# ESP32-C6 register map
Vendor: ESPRESSIF SYSTEMS (SHANGHAI) CO., LTD.; Series: ESP32 C-Series; File version: 12
CPU: RV32IMAC r0p0, little endian, no MPU, no FPU, 0 interrupt priority bits
Address unit: 32 bits
Registers are 32-bit, read-write, reset 0x0 unless marked. A register's access mark holds for its fields unless they carry their own. Offsets are from the block's base; [hi:lo] are bit positions; lines under a group give offsets from that group; {n}, {i} and the like mark numbered series.

## SYSTIMER — System Timer
Base 0x6000A000
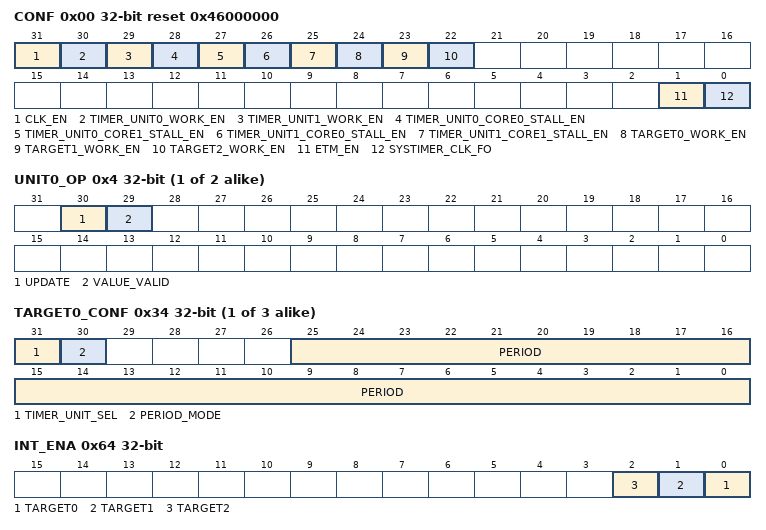
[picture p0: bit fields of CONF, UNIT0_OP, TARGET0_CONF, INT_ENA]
0x00 CONF reset 0x46000000 — Configure system timer clock
  [31] CLK_EN — register file clk gating
  [30] TIMER_UNIT0_WORK_EN — timer unit0 work enable
  [29] TIMER_UNIT1_WORK_EN — timer unit1 work enable
  [28] TIMER_UNIT0_CORE0_STALL_EN — If timer unit0 is stalled when core0 stalled
  [27] TIMER_UNIT0_CORE1_STALL_EN — If timer unit0 is stalled when core1 stalled
  [26] TIMER_UNIT1_CORE0_STALL_EN — If timer unit1 is stalled when core0 stalled
  [25] TIMER_UNIT1_CORE1_STALL_EN — If timer unit1 is stalled when core1 stalled
  [24] TARGET0_WORK_EN — target0 work enable
  [23] TARGET1_WORK_EN — target1 work enable
  [22] TARGET2_WORK_EN — target2 work enable
  [1] ETM_EN — enable systimer's etm task and event
  [0] SYSTIMER_CLK_FO — systimer clock force on
{0x4+4i} UNIT{i}_OP (i=0..1) access per field — system timer unit{i} value update register
  [30] UPDATE wo — update timer_unit0
  [29] VALUE_VALID ro — timer value is sync and valid
{0xC+8i} UNIT{i}LOAD (i=0..1) group — Cluster UNIT{i}LOAD, containing UNIT?_LOAD_HI, UNIT?_LOAD_LO
  0x00 HI — system timer unit0 value high load register
    [19:0] LOAD_HI — timer unit0 load high 20 bits
  0x04 LO — system timer unit0 value low load register
    [31:0] LOAD_LO — timer unit0 load low 32 bits
{0x1C+8i} TRGT{i} (i=0..2) group — Cluster TRGT{i}, containing TARGET?_HI, TARGET?_LO
  0x00 HI — system timer comp0 value high register
    [19:0] HI — timer taget0 high 20 bits
  0x04 LO — system timer comp0 value low register
    [31:0] LO — timer taget0 low 32 bits
{0x34+4i} TARGET{i}_CONF (i=0..2) — system timer comp{i} target mode register
  [31] TIMER_UNIT_SEL — select which unit to compare
  [30] PERIOD_MODE — Set target0 to period mode
  [25:0] PERIOD — target0 period
{0x40+8i} UNIT{i}_VALUE (i=0..1) group — Cluster UNIT{i}_VALUE, containing UNIT?_VALUE_HI, UNIT?_VALUE_LO
  0x00 HI ro — system timer unit0 value high register
    [19:0] VALUE_HI — timer read value high 20bits
  0x04 LO ro — system timer unit0 value low register
    [31:0] VALUE_LO — timer read value low 32bits
{0x50+4i} COMP{i}_LOAD (i=0..2) wo — system timer comp{i} conf sync register
  [0] LOAD — timer comp0 sync enable signal
{0x5C+4i} UNIT{i}_LOAD (i=0..1) wo — system timer unit{i} conf sync register
  [0] LOAD — timer unit0 sync enable signal
0x64 INT_ENA — systimer interrupt enable register
  [n] TARGET{n} (n=0..2) — interupt{n} enable
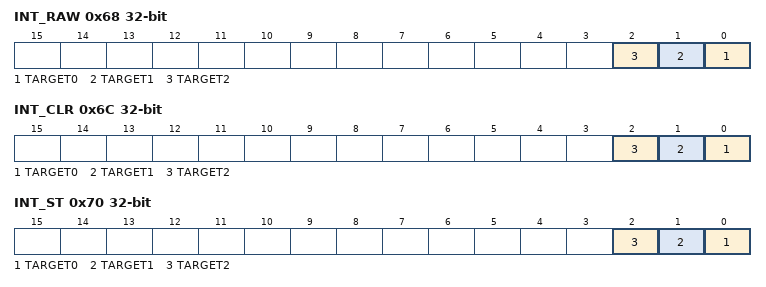
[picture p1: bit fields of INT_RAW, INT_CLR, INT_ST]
0x68 INT_RAW — systimer interrupt raw register
  [n] TARGET{n} (n=0..2) — interupt{n} raw
0x6C INT_CLR wo — systimer interrupt clear register
  [n] TARGET{n} (n=0..2) write-1-clears — interupt{n} clear
0x70 INT_ST ro — systimer interrupt status register
  [n] TARGET{n} (n=0..2) — interupt{n} status
{0x74+8i} REAL_TARGET{i} (i=0..2) group — Cluster REAL_TARGET{i}, containing REAL_TARGET?_LO, REAL_TARGET?_HI
  0x00 LO ro — system timer comp0 actual target value low register
    [31:0] LO_RO — actual target value value low 32bits
  0x04 HI ro — system timer comp0 actual target value high register
    [19:0] HI_RO — actual target value value high 20bits
0xFC DATE — system timer version control register

## TEE — TEE Peripheral
Base 0x60098000
{0x0+4i} M{i}_MODE_CTRL (i=0..31) — Tee mode control register
  [1:0] MODE — M0 security level mode: 2'd3: ree_mode2. 2'd2: ree_mode1. 2'd1: ree_mode0. 2'd0: tee_mode
    0=Tee (Tee mode); 1=Ree0 mode; 2=Ree1 mode; 3=Ree2 mode
0x80 CLOCK_GATE reset 0x1 — Clock gating register
  [0] CLK_EN — reg_clk_en
0xFFC DATE — Version register

## TRACE — RISC-V Trace Encoder
Base 0x600C0000
0x00 MEM_START_ADDR
  [31:0] MEM_START_ADDR — The start address of trace memory
0x04 MEM_END_ADDR reset 0xFFFFFFFF
  [31:0] MEM_END_ADDR — The end address of trace memory
0x08 MEM_CURRENT_ADDR ro
  [31:0] MEM_CURRENT_ADDR — current_mem_addr,indicate that next writing addr
0x0C MEM_ADDR_UPDATE wo
  [0] MEM_CURRENT_ADDR_UPDATE — when set this reg, the current_mem_addr will update to start_addr
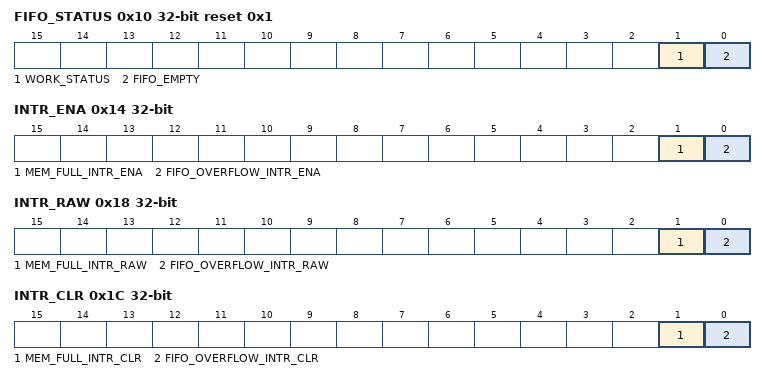
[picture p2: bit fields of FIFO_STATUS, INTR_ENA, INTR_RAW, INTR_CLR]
0x10 FIFO_STATUS ro reset 0x1
  [1] WORK_STATUS — mem_full interrupt status
  [0] FIFO_EMPTY — 1 indicate that fifo is empty
0x14 INTR_ENA — interrupt enable register
  [1] MEM_FULL_INTR_ENA — Set 1 enable mem_full interrupt
  [0] FIFO_OVERFLOW_INTR_ENA — Set 1 enable fifo_overflow interrupt
0x18 INTR_RAW ro — interrupt status register
  [1] MEM_FULL_INTR_RAW — mem_full interrupt status
  [0] FIFO_OVERFLOW_INTR_RAW — fifo_overflow interrupt status
0x1C INTR_CLR wo — interrupt clear register
  [1] MEM_FULL_INTR_CLR — Set 1 clr mem full interrupt
  [0] FIFO_OVERFLOW_INTR_CLR — Set 1 clr fifo overflow interrupt
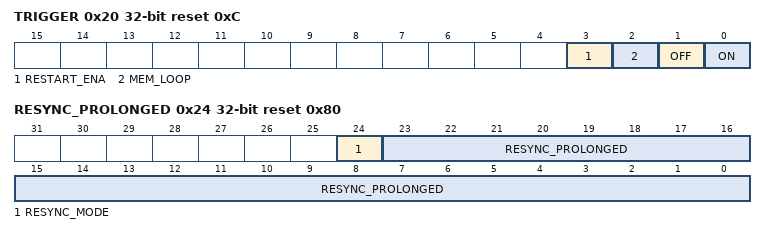
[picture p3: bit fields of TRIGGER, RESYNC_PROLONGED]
0x20 TRIGGER access per field reset 0xC
  [3] RESTART_ENA rw — enable encoder auto-restart, when lost package, the encoder will end, if enable auto-restart, when fifo empty, encoder will restart and send a sync package.
  [2] MEM_LOOP rw — if this reg is 1, trace will loop wrtie trace_mem. If is 0, when mem_current_addr at mem_end_addr, it will stop at the mem_end_addr
  [1] OFF wo — set 1 stop trace.
  [0] ON wo — [0] set 1 start trace.
0x24 RESYNC_PROLONGED reset 0x80 — resync configuration register
  [24] RESYNC_MODE — resyc mode sel: 0: default, cycle count 1: package num count
  [23:0] RESYNC_PROLONGED — count number, when count to this value, send a sync package
0x28 CLOCK_GATE reset 0x1 — Clock gate control register
  [0] CLK_EN — The bit is used to enable clock gate when access all registers in this module.
0x3FC DATE — Version control register
